AUTOSAR XML (schema 4-3-0)
standard types defined: SInt32, UInt16, UInt8, sint32, uint16, uint8
package /DataTypes
  impl type SGaugeInfo_2: category=ARRAY, sw-calibration-access=READ-ONLY, type-emitter=RTE
    element Element: array-size=2, array-size-semantics=FIXED-SIZE, implementation-data-type=SGaugeInfo
package /E40_Platform_System_SystemPackage/Components
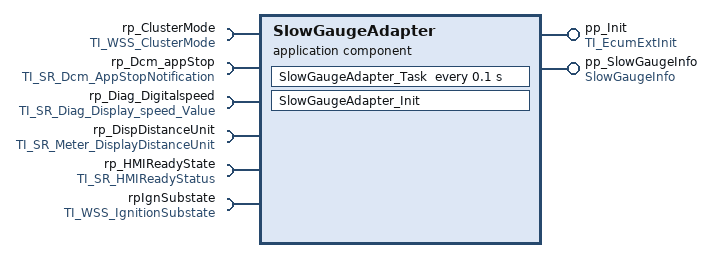
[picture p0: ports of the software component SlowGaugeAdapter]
  application sw component type SlowGaugeAdapter
    provide port pp_Init: server-com-spec{operation=Init, queue-length=1}, provided-interface=TI_EcumExtInit
    provide port pp_SlowGaugeInfo: nonqueued-sender-com-spec{data-element=SlowGaugeInfoData, init-value=constant-reference=SlowGaugeAdapterSlowGaugeInfoDataValue0}, provided-interface=SlowGaugeInfo
    6 x require port:
      rp_ClusterMode: nonqueued-receiver-com-spec{data-element=WSSCurrentClusterMode, filter=data-filter-type=ALWAYS, init-value=constant-reference=SlowGaugeAdapterWSSCurrentClusterModeValue0}, required-interface=TI_WSS_ClusterMode
      rp_Dcm_appStop: nonqueued-receiver-com-spec{data-element=AppId, filter=data-filter-type=ALWAYS, init-value=constant-reference=SlowGaugeAdapterAppIdValue0}, required-interface=TI_SR_Dcm_AppStopNotification
      rp_Diag_Digitalspeed: nonqueued-receiver-com-spec{data-element=Diag_Digital_Speed_Value, filter=data-filter-type=ALWAYS, init-value=constant-reference=SlowGaugeAdapterDiag_Digital_Speed_ValueValue0}, required-interface=TI_SR_Diag_Display_speed_Value
      rp_DispDistanceUnit: nonqueued-receiver-com-spec{data-element=DisplayUnit, filter=data-filter-type=ALWAYS, init-value=constant-reference=SlowGaugeAdapterDisplayUnitValue0}, required-interface=TI_SR_Meter_DisplayDistanceUnit
      rp_HMIReadyState: nonqueued-receiver-com-spec{data-element=HMI_ReadyStatus, filter=data-filter-type=ALWAYS, init-value=constant-reference=SlowGaugeAdapterHMI_ReadyStatusValue0}, required-interface=TI_SR_HMIReadyStatus
      rpIgnSubstate: nonqueued-receiver-com-spec{data-element=IgnitionSubstate, filter=data-filter-type=ALWAYS, init-value=constant-reference=SlowGaugeAdapterIgnitionSubstateValue0}, required-interface=TI_WSS_IgnitionSubstate
    behavior IB_SlowGaugeAdapter
      operation invoked event OIE_pp_Init_SlowGaugeAdapter_InitTrigByInit: start-on-event=SlowGaugeAdapter_Init, operation=pp_Init.Init
      timing event TESlowGaugeAdapter_Task: start-on-event=SlowGaugeAdapter_Task, period=0.1
      port-api-options:
        enable-take-address=false, error-handling=NO-TRANSFORMER-ERROR-HANDLING, indirect-api=false, port=pp_Init
        enable-take-address=false, error-handling=NO-TRANSFORMER-ERROR-HANDLING, indirect-api=false, port=pp_SlowGaugeInfo
        enable-take-address=false, error-handling=NO-TRANSFORMER-ERROR-HANDLING, indirect-api=false, port=rp_ClusterMode
        enable-take-address=false, error-handling=NO-TRANSFORMER-ERROR-HANDLING, indirect-api=false, port=rp_Dcm_appStop
        enable-take-address=false, error-handling=NO-TRANSFORMER-ERROR-HANDLING, indirect-api=false, port=rp_Diag_Digitalspeed
        enable-take-address=false, error-handling=NO-TRANSFORMER-ERROR-HANDLING, indirect-api=false, port=rp_DispDistanceUnit
        enable-take-address=false, error-handling=NO-TRANSFORMER-ERROR-HANDLING, indirect-api=false, port=rp_HMIReadyState
        enable-take-address=false, error-handling=NO-TRANSFORMER-ERROR-HANDLING, indirect-api=false, port=rpIgnSubstate
      runnable SlowGaugeAdapter_Init: can-be-invoked-concurrently=true
      runnable SlowGaugeAdapter_Task: can-be-invoked-concurrently=true
        data-receive-point-by-arguments:
          6 x access:
            DRA_rp_ClusterMode_WSSCurrentClusterMode: accessed-variable=rp_ClusterMode.WSSCurrentClusterMode
            DRA_rp_Dcm_appStop_AppId: accessed-variable=rp_Dcm_appStop.AppId
            DRA_rp_Diag_Digitalspeed_Diag_Digital_Speed_Value: accessed-variable=rp_Diag_Digitalspeed.Diag_Digital_Speed_Value
            DRA_rp_DispDistanceUnit_DisplayUnit: accessed-variable=rp_DispDistanceUnit.DisplayUnit
            DRA_rp_HMIReadyState_HMI_ReadyStatus: accessed-variable=rp_HMIReadyState.HMI_ReadyStatus
            DRA_rpIgnSubstate_IgnitionSubstate: accessed-variable=rpIgnSubstate.IgnitionSubstate
        data-send-points:
          access DWA_pp_SlowGaugeInfo_SlowGaugeInfoData: accessed-variable=pp_SlowGaugeInfo.SlowGaugeInfoData
  7 x constant specification:
    SlowGaugeAdapterAppIdValue0: value-spec=SlowGaugeAdapterAppIdValue0:0
    SlowGaugeAdapterDiag_Digital_Speed_ValueValue0: value-spec=SlowGaugeAdapterDiag_Digital_Speed_ValueValue0:0
    SlowGaugeAdapterDisplayUnitValue0: value-spec=SlowGaugeAdapterDisplayUnitValue0:0
    SlowGaugeAdapterHMI_ReadyStatusValue0: value-spec=SlowGaugeAdapterHMI_ReadyStatusValue0:0
    SlowGaugeAdapterIgnitionSubstateValue0: value-spec=SlowGaugeAdapterIgnitionSubstateValue0:0
    SlowGaugeAdapterSlowGaugeInfoDataValue0: value-spec={short-label=SlowGaugeAdapterSlowGaugeInfoDataValue0, fields=gaugeInfo:[fields=[id:0, position:0, digitalData:0, unit:0, dynData:0], fields=[id:0, position:0, digitalData:0, unit:0, dynData:0]]}
    SlowGaugeAdapterWSSCurrentClusterModeValue0: value-spec=SlowGaugeAdapterWSSCurrentClusterModeValue0:0
  swc implementation IMPL_SlowGaugeAdapter: behavior=IB_SlowGaugeAdapter
    code-descriptors:
      code Default: artifact-descriptors=autosar-engineering-object={short-label=Default, category=SWSRC}
package /E40_Platform_System_SystemPackage/Types
  client server interface TI_EcumExtInit
    operation Init
  7 x impl type:
    ClusterModes: category=VALUE, base-type=uint8, compu {0=CLUSTER_INACTIVE, 1=CLUSTER_ACTIVE}, range raw 0..1
    EGaugeUnit: category=VALUE, base-type=uint8, compu {0=EGaugeUnit_Mph, 1=EGaugeUnit_Kmph, 2=EGaugeUnit_Centigrade, 3=EGaugeUnit_Farenheit, 4=EGaugeUnit_Psi, 5=EGaugeUnit_Pa, 6=EGaugeUnit_Bar, 7=EGaugeUnit_Last}, range raw 0..7
    HMIReadySts_Type: category=VALUE, base-type=uint8, compu {0=eHMI_NOT_READY, 1=eHMI_READY}, range raw 0..1
    IgntionSubstateType: category=VALUE, base-type=uint8, compu {0=IgnOff, 1=IgnOn}, range raw 0..1
    IOCtrl_Type: category=VALUE, base-type=uint8, compu {1=eSPEEDO, 2=eTACHO, 4=eHVSYS_INDICATOR, 8=eSPEAKER, 16=eTELLTALE, 32=eBUTTONEVENT, 64=eMIDDISPALY}, range raw 1..64
    SGaugeInfo: category=STRUCTURE
      5 x element, all with category=TYPE_REFERENCE:
        id: implementation-data-type=UInt8
        position: implementation-data-type=UInt16
        digitalData: implementation-data-type=SInt32
        unit: implementation-data-type=EGaugeUnit
        dynData: implementation-data-type=UInt16
    SSlowGaugeInfo: category=STRUCTURE
      element gaugeInfo: implementation-data-type=SGaugeInfo_2
  7 x sender receiver interface:
    SlowGaugeInfo: invalidation-policy{data-element=SlowGaugeInfoData, handle-invalid=DONT-INVALIDATE}
      data SlowGaugeInfoData: type=SSlowGaugeInfo
    TI_SR_Dcm_AppStopNotification: invalidation-policy{data-element=AppId, handle-invalid=DONT-INVALIDATE}
      data AppId: type=IOCtrl_Type
    TI_SR_Diag_Display_speed_Value: invalidation-policy{data-element=Diag_Digital_Speed_Value, handle-invalid=DONT-INVALIDATE}
      data Diag_Digital_Speed_Value: type=UInt16
    TI_SR_HMIReadyStatus: invalidation-policy{data-element=HMI_ReadyStatus, handle-invalid=DONT-INVALIDATE}
      data HMI_ReadyStatus: type=HMIReadySts_Type
    TI_SR_Meter_DisplayDistanceUnit: invalidation-policy{data-element=DisplayUnit, handle-invalid=DONT-INVALIDATE}
      data DisplayUnit: type=UInt8
    TI_WSS_ClusterMode: invalidation-policy{data-element=WSSCurrentClusterMode, handle-invalid=DONT-INVALIDATE}
      data WSSCurrentClusterMode: type=ClusterModes
    TI_WSS_IgnitionSubstate: invalidation-policy{data-element=IgnitionSubstate, handle-invalid=DONT-INVALIDATE}
      data IgnitionSubstate: type=IgntionSubstateType
package /E40_Platform_System_SystemPackage/Types/DataConstrs
  range SInt32_DataConstraint: raw -2147483648..2147483647
  range UInt16_DataConstraint: raw 0..65535
  range UInt8_DataConstraint: raw 0..255
